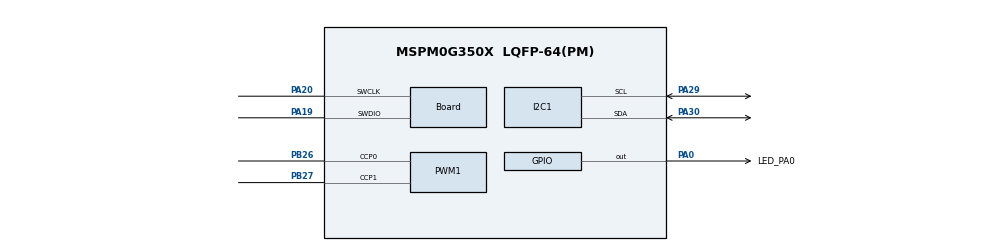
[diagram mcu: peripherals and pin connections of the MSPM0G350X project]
/**
 * @cliArgs --device "MSPM0G350X" --package "LQFP-64(PM)" --part "Default" --product "mspm0_sdk@2.00.01.00"
 * @versions {"tool":"1.20.0+3587"}
 */

/**
 * Import the modules used in this configuration.
 */
const GPIO          = scripting.addModule("/ti/driverlib/GPIO", {}, false);
const GPIO1         = GPIO.addInstance();
const I2C           = scripting.addModule("/ti/driverlib/I2C", {}, false);
const I2C1          = I2C.addInstance();
const PWM           = scripting.addModule("/ti/driverlib/PWM", {}, false);
const PWM1          = PWM.addInstance();
const SYSCTL        = scripting.addModule("/ti/driverlib/SYSCTL");
const TIMER         = scripting.addModule("/ti/driverlib/TIMER", {}, false);
const TIMER1        = TIMER.addInstance();
const ProjectConfig = scripting.addModule("/ti/project_config/ProjectConfig");

/**
 * Write custom configuration values to the imported modules.
 */
GPIO1.port                          = "PORTA";
GPIO1.$name                         = "USER_GPIO";
GPIO1.associatedPins[0].$name       = "LED_PA0";
GPIO1.associatedPins[0].pin.$assign = "PA0";

const Board                       = scripting.addModule("/ti/driverlib/Board", {}, false);
Board.peripheral.$assign          = "DEBUGSS";
Board.peripheral.swclkPin.$assign = "PA20";
Board.peripheral.swdioPin.$assign = "PA19";

I2C1.$name                     = "I2C_0";
I2C1.basicEnableController     = true;
I2C1.peripheral.$assign        = "I2C1";
I2C1.peripheral.sdaPin.$assign = "PA30";
I2C1.peripheral.sclPin.$assign = "PA29";
I2C1.sdaPinConfig.$name        = "ti_driverlib_gpio_GPIOPinGeneric0";
I2C1.sclPinConfig.$name        = "ti_driverlib_gpio_GPIOPinGeneric1";

PWM1.$name                      = "PWM_1";
PWM1.pwmMode                    = "EDGE_ALIGN_UP";
PWM1.peripheral.ccp0Pin.$assign = "PB26";
PWM1.peripheral.ccp1Pin.$assign = "PB27";
PWM1.PWM_CHANNEL_0.$name        = "ti_driverlib_pwm_PWMTimerCC2";
PWM1.PWM_CHANNEL_1.$name        = "ti_driverlib_pwm_PWMTimerCC3";
PWM1.ccp0PinConfig.$name        = "ti_driverlib_gpio_GPIOPinGeneric4";
PWM1.ccp1PinConfig.$name        = "ti_driverlib_gpio_GPIOPinGeneric5";

SYSCTL.clockTreeEn = true;

TIMER1.$name              = "TIMER_0";
TIMER1.timerPeriod        = "100 ms";
TIMER1.timerClkPrescale   = 100;
TIMER1.timerMode          = "PERIODIC_UP";
TIMER1.interrupts         = ["ZERO"];
TIMER1.peripheral.$assign = "TIMG0";

ProjectConfig.deviceSpin = "MSPM0G3507";

/**
 * Pinmux solution for unlocked pins/peripherals. This ensures that minor changes to the automatic solver in a future
 * version of the tool will not impact the pinmux you originally saw.  These lines can be completely deleted in order to
 * re-solve from scratch.
 */
PWM1.peripheral.$suggestSolution = "TIMA1";
